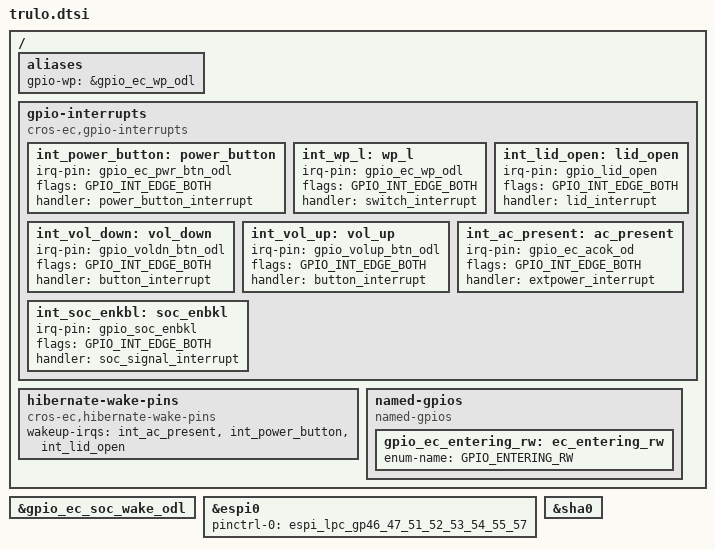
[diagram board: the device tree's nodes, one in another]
/* Copyright 2024 The ChromiumOS Authors
 * Use of this source code is governed by a BSD-style license that can be
 * found in the LICENSE file.
 */

#include <cros/integrated_fwid.dtsi>

/ {
	aliases {
		gpio-wp = &gpio_ec_wp_odl;
	};

	gpio-interrupts {
		compatible = "cros-ec,gpio-interrupts";

		int_power_button: power_button {
			irq-pin = <&gpio_ec_pwr_btn_odl>;
			flags = <GPIO_INT_EDGE_BOTH>;
			handler = "power_button_interrupt";
		};
		int_wp_l: wp_l {
			irq-pin = <&gpio_ec_wp_odl>;
			flags = <GPIO_INT_EDGE_BOTH>;
			handler = "switch_interrupt";
		};
		int_lid_open: lid_open {
			irq-pin = <&gpio_lid_open>;
			flags = <GPIO_INT_EDGE_BOTH>;
			handler = "lid_interrupt";
		};
		int_vol_down: vol_down {
			irq-pin = <&gpio_voldn_btn_odl>;
			flags = <GPIO_INT_EDGE_BOTH>;
			handler = "button_interrupt";
		};
		int_vol_up: vol_up {
			irq-pin = <&gpio_volup_btn_odl>;
			flags = <GPIO_INT_EDGE_BOTH>;
			handler = "button_interrupt";
		};
		int_ac_present: ac_present {
			irq-pin = <&gpio_ec_acok_od>;
			flags = <GPIO_INT_EDGE_BOTH>;
			handler = "extpower_interrupt";
		};
		int_soc_enkbl: soc_enbkl {
			irq-pin = <&gpio_soc_enbkl>;
			flags = <GPIO_INT_EDGE_BOTH>;
			handler = "soc_signal_interrupt";
		};
	};

	hibernate-wake-pins {
		compatible = "cros-ec,hibernate-wake-pins";
		wakeup-irqs = <&int_ac_present
			       &int_power_button
			       &int_lid_open>;
	};

	named-gpios {
		compatible = "named-gpios";

		/* The legacy system code requires GPIO_ENTERING_RW symbol */
		gpio_ec_entering_rw: ec_entering_rw {
			enum-name = "GPIO_ENTERING_RW";
		};
	};
};

/* The eSPI shim requires this GPIO nodelabel */
gpio_ec_pch_wake_odl: &gpio_ec_soc_wake_odl {
};


/* host interface */
&espi0 {
	status = "okay";
	pinctrl-0 = <&espi_lpc_gp46_47_51_52_53_54_55_57>;
	pinctrl-names = "default";
};

&sha0 {
	status = "okay";
};
